AUTOSAR XML (schema 4-1-2)
package /ComponentTypes
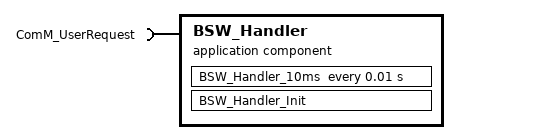
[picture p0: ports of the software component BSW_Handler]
  application sw component type BSW_Handler
    require port ComM_UserRequest: required-com-specs=[GetRequestedComMode, GetMaxComMode, GetCurrentComMode, RequestComMode], required-interface=ComM_UserRequest
    behavior BSW_Handler_InternalBehavior
      timing event TMT_LightCtrl: start-on-event=BSW_Handler_10ms, period=0.01
      init event BSW_Handler_InitEvent: start-on-event=BSW_Handler_Init
      runnable BSW_Handler_10ms
        sync call SC_ComM_UserRequest_GetCurrentComMode: operation=ComM_UserRequest.GetCurrentComMode, timeout=0
        sync call SC_ComM_UserRequest_RequestComMode: operation=ComM_UserRequest.RequestComMode, timeout=0
      runnable BSW_Handler_Init
        sync call SC_ComM_UserRequest_RequestComMode: operation=ComM_UserRequest.RequestComMode, timeout=0
  swc implementation BSW_Handler_Implementation: behavior=BSW_Handler_InternalBehavior
    code-descriptors:
      code Default: artifact-descriptors=autosar-engineering-object={short-label=Default, category=SWSRC}
